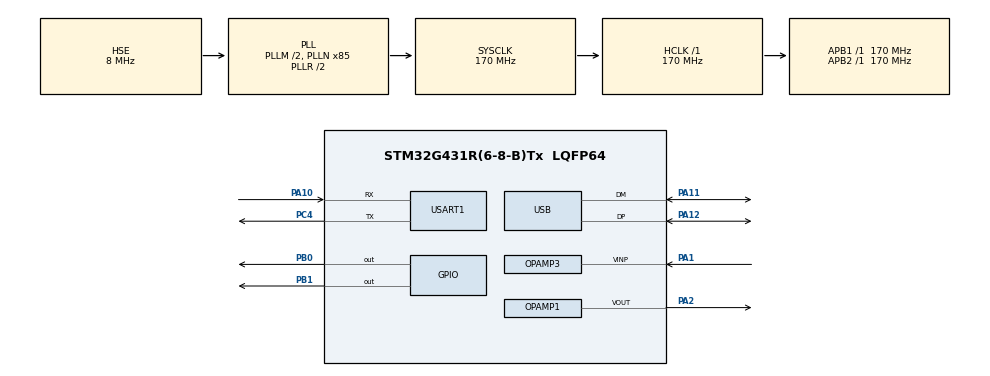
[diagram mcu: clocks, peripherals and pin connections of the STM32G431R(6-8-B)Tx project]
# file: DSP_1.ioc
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ADC2.Channel-1\#ChannelRegularConversion=ADC_CHANNEL_VOPAMP3_ADC2
ADC2.ClockPrescaler=ADC_CLOCK_SYNC_PCLK_DIV4
ADC2.ContinuousConvMode=ENABLE
ADC2.DMAContinuousRequests=ENABLE
ADC2.EnableRegularConversion=ENABLE
ADC2.ExternalTrigConv=ADC_EXTERNALTRIG_T6_TRGO
ADC2.NbrOfConversionFlag=1
ADC2.OffsetNumber-1\#ChannelRegularConversion=ADC_OFFSET_NONE
ADC2.Rank-1\#ChannelRegularConversion=1
ADC2.SamplingTime-1\#ChannelRegularConversion=ADC_SAMPLETIME_2CYCLES_5
Dma.ADC2.0.Direction=DMA_PERIPH_TO_MEMORY
Dma.ADC2.0.EventEnable=DISABLE
Dma.ADC2.0.Instance=DMA1_Channel1
Dma.ADC2.0.MemDataAlignment=DMA_MDATAALIGN_HALFWORD
Dma.ADC2.0.MemInc=DMA_MINC_ENABLE
Dma.ADC2.0.Mode=DMA_NORMAL
Dma.ADC2.0.PeriphDataAlignment=DMA_PDATAALIGN_HALFWORD
Dma.ADC2.0.PeriphInc=DMA_PINC_DISABLE
Dma.ADC2.0.Polarity=HAL_DMAMUX_REQ_GEN_RISING
Dma.ADC2.0.Priority=DMA_PRIORITY_LOW
Dma.ADC2.0.RequestNumber=1
Dma.ADC2.0.SignalID=NONE
Dma.ADC2.0.SyncEnable=DISABLE
Dma.ADC2.0.SyncPolarity=HAL_DMAMUX_SYNC_NO_EVENT
Dma.ADC2.0.SyncRequestNumber=1
Dma.ADC2.0.SyncSignalID=NONE
Dma.Request0=ADC2
Mcu.Family=STM32G4
Mcu.Name=STM32G431R(6-8-B)Tx
Mcu.Package=LQFP64
NVIC.DMA1_Channel1_IRQn=true\:0\:0\:false\:false\:true\:false\:true\:true
NVIC.PriorityGroup=NVIC_PRIORITYGROUP_4
NVIC.USB_LP_IRQn=true\:0\:0\:false\:false\:true\:false\:true\:true
OPAMP1.PowerMode=OPAMP_POWERMODE_HIGHSPEED
OPAMP3.PowerMode=OPAMP_POWERMODE_HIGHSPEED
PA1.Mode=PGA_Internally_Connected
PA1.Signal=OPAMP3_VINP
PA10.Mode=Asynchronous
PA10.Signal=USART1_RX
PA11.Mode=Device
PA11.Signal=USB_DM
PA12.Mode=Device
PA12.Signal=USB_DP
PA13.Mode=Serial_Wire
PA13.Signal=SYS_JTMS-SWDIO
PA14.Mode=Serial_Wire
PA14.Signal=SYS_JTCK-SWCLK
PA2.Mode=Follower-DAC_OUT2-INP
PA2.Signal=OPAMP1_VOUT
PB0.Signal=GPIO_Output
PB1.Signal=GPIO_Output
PC4.Mode=Asynchronous
PC4.Signal=USART1_TX
PF0-OSC_IN.Mode=HSE-External-Oscillator
PF0-OSC_IN.Signal=RCC_OSC_IN
PF1-OSC_OUT.Mode=HSE-External-Oscillator
PF1-OSC_OUT.Signal=RCC_OSC_OUT
ProjectManager.HeapSize=0x200
ProjectManager.StackSize=0x400
ProjectManager.TargetToolchain=STM32CubeIDE
RCC.ADC12Freq_Value=170000000
RCC.AHBFreq_Value=170000000
RCC.APB1Freq_Value=170000000
RCC.APB1TimFreq_Value=170000000
RCC.APB2Freq_Value=170000000
RCC.APB2TimFreq_Value=170000000
RCC.CK48CLockSelection=RCC_USBCLKSOURCE_HSI48
RCC.CortexFreq_Value=170000000
RCC.EXTERNAL_CLOCK_VALUE=12288000
RCC.HCLKFreq_Value=170000000
RCC.HSE_VALUE=8000000
RCC.HSI48_VALUE=48000000
RCC.HSI_VALUE=16000000
RCC.LSE_VALUE=32768
RCC.PLLM=RCC_PLLM_DIV2
RCC.PLLN=85
RCC.PLLSourceVirtual=RCC_PLLSOURCE_HSE
RCC.SYSCLKFreq_VALUE=170000000
RCC.SYSCLKSource=RCC_SYSCLKSOURCE_PLLCLK
RCC.USBFreq_Value=48000000
RCC.VCOOutputFreq_Value=340000000
SYS.VoltageScaling=SYSCFG_VREFBUF_VOLTAGE_SCALE2
TIM6.PeriodNoDither=2-1
TIM6.Prescaler=170-1
TIM6.TIM_MasterOutputTrigger=TIM_TRGO_UPDATE
USART1.VirtualMode-Asynchronous=VM_ASYNC
USB_DEVICE.CLASS_NAME_FS=CDC
USB_DEVICE.VirtualMode=Cdc
USB_DEVICE.VirtualModeFS=Cdc_FS
VP_ADC2_OPAMP_INTERNAL3.Mode=IN-OPAMP3
VP_CORDIC_VS_CORDIC.Mode=CORDIC_Activate
VP_DAC3_VS_DACI1.Mode=DAC_OUT1_Int
VP_FMAC_VS_FMAC.Mode=FMAC_Activate
VP_SYS_VS_DBSignals.Mode=DisableDeadBatterySignals
VP_TIM6_VS_ClockSourceINT.Mode=Enable_Timer
VP_USB_DEVICE_VS_USB_DEVICE_CDC_FS.Mode=CDC_FS
VREF+.Mode=InternalMode
VREF+.Signal=VREFBUF_OUT
board=custom

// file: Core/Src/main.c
/* USER CODE BEGIN Header */
/* USER CODE END Header */
#include "main.h"
#include "adc.h"
#include "cordic.h"
#include "dac.h"
#include "dma.h"
#include "fmac.h"
#include "opamp.h"
#include "tim.h"
#include "usart.h"
#include "usb_device.h"
#include "gpio.h"

/* USER CODE BEGIN PV */

extern USBD_HandleTypeDef hUsbDeviceFS;

uint16_t CDC_BUFFER[2048]={0};
uint16_t ADC_BUFFER[2048]={0};
uint16_t DAC_BUFFER[2048]={0};

/* USER CODE END PV */

void SystemClock_Config(void);

int main(void)
{

  /* MCU Configuration--------------------------------------------------------*/

  /* Reset of all peripherals, Initializes the Flash interface and the Systick. */
  HAL_Init();

  /* Configure the system clock */
  SystemClock_Config();

  /* Initialize all configured peripherals */
  MX_GPIO_Init();
  MX_DMA_Init();
  MX_ADC2_Init();
  MX_DAC3_Init();
  MX_OPAMP1_Init();
  MX_OPAMP3_Init();
  MX_USB_Device_Init();
  MX_FMAC_Init();
  MX_CORDIC_Init();
  MX_TIM6_Init();
  MX_USART1_UART_Init();
  /* USER CODE BEGIN 2 */

  HAL_OPAMP_Start(&hopamp1);
  HAL_OPAMP_Start(&hopamp3);

  HAL_Delay(100);
  HAL_ADC_Start_DMA(&hadc2,ADC_BUFFER, 1024);
  HAL_TIM_Base_Start(&htim6);

  /* USER CODE END 2 */

  /* Infinite loop */
  /* USER CODE BEGIN WHILE */
  while(1){
//	  HAL_ADC_StartSampling(&hadc2);
//	  HAL_ADC_Start(&hadc2);

	  for (int i = 0; i < 1024; i++) {
	  sprintf(CDC_BUFFER,"IN: %d \r\n",ADC_BUFFER[i]);
	  CDC_Transmit_FS(CDC_BUFFER, 20);
//	  HAL_Delay(1);
	  }
  }
    /* USER CODE END WHILE */

}

void SystemClock_Config(void)
{
  RCC_OscInitTypeDef RCC_OscInitStruct = {0};
  RCC_ClkInitTypeDef RCC_ClkInitStruct = {0};

  /** Configure the main internal regulator output voltage
  */
  HAL_PWREx_ControlVoltageScaling(PWR_REGULATOR_VOLTAGE_SCALE1_BOOST);

  /** Initializes the RCC Oscillators according to the specified parameters
  * in the RCC_OscInitTypeDef structure.
  */
  RCC_OscInitStruct.OscillatorType = RCC_OSCILLATORTYPE_HSI48|RCC_OSCILLATORTYPE_HSE;
  RCC_OscInitStruct.HSEState = RCC_HSE_ON;
  RCC_OscInitStruct.HSI48State = RCC_HSI48_ON;
  RCC_OscInitStruct.PLL.PLLState = RCC_PLL_ON;
  RCC_OscInitStruct.PLL.PLLSource = RCC_PLLSOURCE_HSE;
  RCC_OscInitStruct.PLL.PLLM = RCC_PLLM_DIV2;
  RCC_OscInitStruct.PLL.PLLN = 85;
  RCC_OscInitStruct.PLL.PLLP = RCC_PLLP_DIV2;
  RCC_OscInitStruct.PLL.PLLQ = RCC_PLLQ_DIV2;
  RCC_OscInitStruct.PLL.PLLR = RCC_PLLR_DIV2;
  if (HAL_RCC_OscConfig(&RCC_OscInitStruct) != HAL_OK)
  {
    Error_Handler();
  }

  /** Initializes the CPU, AHB and APB buses clocks
  */
  RCC_ClkInitStruct.ClockType = RCC_CLOCKTYPE_HCLK|RCC_CLOCKTYPE_SYSCLK
                              |RCC_CLOCKTYPE_PCLK1|RCC_CLOCKTYPE_PCLK2;
  RCC_ClkInitStruct.SYSCLKSource = RCC_SYSCLKSOURCE_PLLCLK;
  RCC_ClkInitStruct.AHBCLKDivider = RCC_SYSCLK_DIV1;
  RCC_ClkInitStruct.APB1CLKDivider = RCC_HCLK_DIV1;
  RCC_ClkInitStruct.APB2CLKDivider = RCC_HCLK_DIV1;

  if (HAL_RCC_ClockConfig(&RCC_ClkInitStruct, FLASH_LATENCY_4) != HAL_OK)
  {
    Error_Handler();
  }
}

void Error_Handler(void)
{
}
